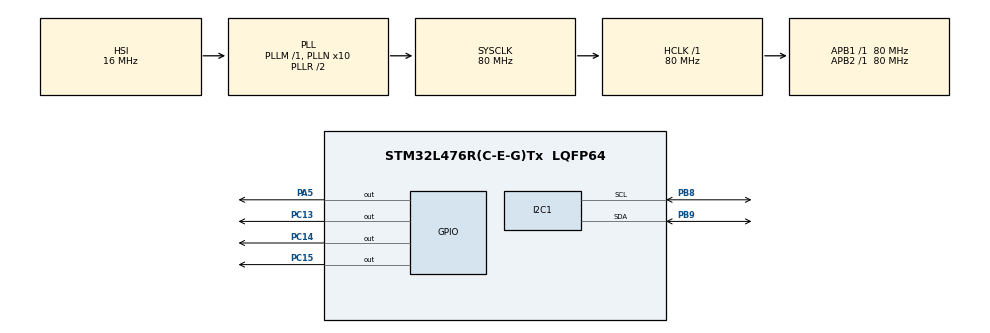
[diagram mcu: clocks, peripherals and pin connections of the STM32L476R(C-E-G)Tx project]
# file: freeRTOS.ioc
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FREERTOS.INCLUDE_eTaskGetState=1
FREERTOS.INCLUDE_pcTaskGetTaskName=1
FREERTOS.INCLUDE_uxTaskGetStackHighWaterMark=1
FREERTOS.INCLUDE_uxTaskGetStackHighWaterMark2=1
FREERTOS.INCLUDE_vTaskCleanUpResources=1
FREERTOS.INCLUDE_xQueueGetMutexHolder=1
FREERTOS.INCLUDE_xSemaphoreGetMutexHolder=1
FREERTOS.INCLUDE_xTaskAbortDelay=1
FREERTOS.INCLUDE_xTaskGetCurrentTaskHandle=1
FREERTOS.INCLUDE_xTaskGetHandle=1
FREERTOS.Tasks01=defaultTask,0,128,StartDefaultTask,Default,NULL,Dynamic,NULL,NULL
FREERTOS.configUSE_NEWLIB_REENTRANT=1
I2C1.Timing=0x10909CEC
Mcu.Family=STM32L4
Mcu.Name=STM32L476R(C-E-G)Tx
Mcu.Package=LQFP64
NVIC.PriorityGroup=NVIC_PRIORITYGROUP_4
PA4.Signal=SPI1_NSS
PA5.Signal=GPIO_Output
PA6.Signal=SPI1_MISO
PA7.Signal=SPI1_MOSI
PB8.Mode=I2C
PB8.Signal=I2C1_SCL
PB9.Mode=I2C
PB9.Signal=I2C1_SDA
PC13.Signal=GPIO_Output
PC14-OSC32_IN\ (PC14).Signal=GPIO_Output
PC15-OSC32_OUT\ (PC15).Signal=GPIO_Output
ProjectManager.HeapSize=0x200
ProjectManager.StackSize=0x400
ProjectManager.TargetToolchain=STM32CubeIDE
RCC.ADCFreq_Value=64000000
RCC.AHBFreq_Value=80000000
RCC.APB1Freq_Value=80000000
RCC.APB1TimFreq_Value=80000000
RCC.APB2Freq_Value=80000000
RCC.APB2TimFreq_Value=80000000
RCC.CortexFreq_Value=80000000
RCC.HCLKFreq_Value=80000000
RCC.HSE_VALUE=8000000
RCC.HSI_VALUE=16000000
RCC.LSE_VALUE=32768
RCC.MSI_VALUE=4000000
RCC.PLLN=10
RCC.PLLSourceVirtual=RCC_PLLSOURCE_HSI
RCC.PREFETCH_ENABLE=1
RCC.SYSCLKFreq_VALUE=80000000
RCC.SYSCLKSource=RCC_SYSCLKSOURCE_PLLCLK
RCC.USBFreq_Value=64000000
RCC.VCOOutputFreq_Value=160000000
VP_FREERTOS_VS_CMSIS_V1.Mode=CMSIS_V1
board=NUCLEO-L476RG

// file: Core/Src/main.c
/* USER CODE BEGIN Header */
/**
  ******************************************************************************
  * @file           : main.c
  * @brief          : Main program body
  ******************************************************************************
  * @attention
  *
  * Copyright (c) 2023 STMicroelectronics.
  * All rights reserved.
  *
  * This software is licensed under terms that can be found in the LICENSE file
  * in the root directory of this software component.
  * If no LICENSE file comes with this software, it is provided AS-IS.
  *
  ******************************************************************************
  */
/* USER CODE END Header */
#include "main.h"
#include "cmsis_os.h"

/* USER CODE BEGIN Includes */
#include "FreeRTOS.h"
#include "task.h"
#include "main.h"
/* USER CODE END Includes */

I2C_HandleTypeDef hi2c1;

osThreadId defaultTaskHandle;

void SystemClock_Config(void);
static void MX_GPIO_Init(void);
static void MX_I2C1_Init(void);
static void MX_SPI1_Init(void);
void StartDefaultTask(void const * argument);

/* USER CODE BEGIN 0 */

/* USER CODE BEGIN PFP */
static void led_green_function(void* params);
static void led_orange_function(void* params);
static void led_red_function(void* params);
//static void led_blue_function(void* params);
/* USER CODE END 0 */

int main(void)
{

  /* MCU Configuration--------------------------------------------------------*/

  /* Reset of all peripherals, Initializes the Flash interface and the Systick. */
  HAL_Init();

  /* Configure the system clock */
  SystemClock_Config();

  /* Initialize all configured peripherals */
  MX_GPIO_Init();
  MX_I2C1_Init();

  /* Create the thread(s) */
  /* definition and creation of defaultTask */
  osThreadDef(defaultTask, StartDefaultTask, osPriorityNormal, 0, 128);
  defaultTaskHandle = osThreadCreate(osThread(defaultTask), NULL);

  TaskHandle_t led_green, led_red, led_orange; //led_blue, button;
	BaseType_t status;
  status = xTaskCreate(led_green_function, "Green LED", 200, NULL, 2, &led_green);
  configASSERT(status == pdPASS);

	status = xTaskCreate(led_orange_function, "Orange LED", 200, NULL, 2, &led_orange);
	  configASSERT(status == pdPASS);

	  //Task 3
	  status = xTaskCreate(led_red_function, "Red LED", 200, NULL, 2, &led_red);
	  configASSERT(status == pdPASS);

	  //Task 4
	 // status = xTaskCreate(led_blue_function, "Blue LED", 200, NULL, 2, &led_blue);

	  vTaskStartScheduler();
  /* Start scheduler */
  osKernelStart();
  /* We should never get here as control is now taken by the scheduler */
  /* Infinite loop */
  while (1)
  {

  }
}

void SystemClock_Config(void)
{
  RCC_OscInitTypeDef RCC_OscInitStruct = {0};
  RCC_ClkInitTypeDef RCC_ClkInitStruct = {0};

  /** Configure the main internal regulator output voltage
  */
  if (HAL_PWREx_ControlVoltageScaling(PWR_REGULATOR_VOLTAGE_SCALE1) != HAL_OK)
  {
    Error_Handler();
  }

  /** Initializes the RCC Oscillators according to the specified parameters
  * in the RCC_OscInitTypeDef structure.
  */
  RCC_OscInitStruct.OscillatorType = RCC_OSCILLATORTYPE_HSI;
  RCC_OscInitStruct.HSIState = RCC_HSI_ON;
  RCC_OscInitStruct.HSICalibrationValue = RCC_HSICALIBRATION_DEFAULT;
  RCC_OscInitStruct.PLL.PLLState = RCC_PLL_ON;
  RCC_OscInitStruct.PLL.PLLSource = RCC_PLLSOURCE_HSI;
  RCC_OscInitStruct.PLL.PLLM = 1;
  RCC_OscInitStruct.PLL.PLLN = 10;
  RCC_OscInitStruct.PLL.PLLP = RCC_PLLP_DIV7;
  RCC_OscInitStruct.PLL.PLLQ = RCC_PLLQ_DIV2;
  RCC_OscInitStruct.PLL.PLLR = RCC_PLLR_DIV2;
  if (HAL_RCC_OscConfig(&RCC_OscInitStruct) != HAL_OK)
  {
    Error_Handler();
  }

  /** Initializes the CPU, AHB and APB buses clocks
  */
  RCC_ClkInitStruct.ClockType = RCC_CLOCKTYPE_HCLK|RCC_CLOCKTYPE_SYSCLK
                              |RCC_CLOCKTYPE_PCLK1|RCC_CLOCKTYPE_PCLK2;
  RCC_ClkInitStruct.SYSCLKSource = RCC_SYSCLKSOURCE_PLLCLK;
  RCC_ClkInitStruct.AHBCLKDivider = RCC_SYSCLK_DIV1;
  RCC_ClkInitStruct.APB1CLKDivider = RCC_HCLK_DIV1;
  RCC_ClkInitStruct.APB2CLKDivider = RCC_HCLK_DIV1;

  if (HAL_RCC_ClockConfig(&RCC_ClkInitStruct, FLASH_LATENCY_4) != HAL_OK)
  {
    Error_Handler();
  }
}

static void MX_I2C1_Init(void)
{

  hi2c1.Instance = I2C1;
  hi2c1.Init.Timing = 0x10909CEC;
  hi2c1.Init.OwnAddress1 = 0;
  hi2c1.Init.AddressingMode = I2C_ADDRESSINGMODE_7BIT;
  hi2c1.Init.DualAddressMode = I2C_DUALADDRESS_DISABLE;
  hi2c1.Init.OwnAddress2 = 0;
  hi2c1.Init.OwnAddress2Masks = I2C_OA2_NOMASK;
  hi2c1.Init.GeneralCallMode = I2C_GENERALCALL_DISABLE;
  hi2c1.Init.NoStretchMode = I2C_NOSTRETCH_DISABLE;
  if (HAL_I2C_Init(&hi2c1) != HAL_OK)
  {
    Error_Handler();
  }

  /** Configure Analogue filter
  */
  if (HAL_I2CEx_ConfigAnalogFilter(&hi2c1, I2C_ANALOGFILTER_ENABLE) != HAL_OK)
  {
    Error_Handler();
  }

  /** Configure Digital filter
  */
  if (HAL_I2CEx_ConfigDigitalFilter(&hi2c1, 0) != HAL_OK)
  {
    Error_Handler();
  }

}

static void MX_GPIO_Init(void)
{
  GPIO_InitTypeDef GPIO_InitStruct = {0};

  /* GPIO Ports Clock Enable */
  __HAL_RCC_GPIOC_CLK_ENABLE();
  __HAL_RCC_GPIOA_CLK_ENABLE();
  __HAL_RCC_GPIOB_CLK_ENABLE();

  /*Configure GPIO pin Output Level */
  HAL_GPIO_WritePin(GPIOC, GPIO_PIN_13|GPIO_PIN_14|GPIO_PIN_15, GPIO_PIN_RESET);

  /*Configure GPIO pins : PC13 PC14 PC15 */
  GPIO_InitStruct.Pin = GPIO_PIN_13|GPIO_PIN_14|GPIO_PIN_15;
  GPIO_InitStruct.Mode = GPIO_MODE_OUTPUT_PP;
  GPIO_InitStruct.Pull = GPIO_NOPULL;
  GPIO_InitStruct.Speed = GPIO_SPEED_FREQ_LOW;
  HAL_GPIO_Init(GPIOC, &GPIO_InitStruct);

}

void StartDefaultTask(void const * argument)
{
  for(;;)
  {
    osDelay(1);
  }
}
static void led_green_function(void* params)
{
	TickType_t last_wakeup = xTaskGetTickCount();
	while(1)
	{
		printf("Green LED Task\n");
		HAL_GPIO_TogglePin(GPIOC, 13);
//		HAL_Delay(1000);
		vTaskDelay( pdMS_TO_TICKS( 1000 ) );
//		vTaskDelayUntil(&last_wakeup, pdMS_TO_TICKS( 250 ) );
	}
}

static void led_orange_function(void* params)
{
	TickType_t last_wakeup = xTaskGetTickCount();
	while(1)
	{
		printf("Orange LED Task\n");
		HAL_GPIO_TogglePin(GPIOC, 14);
//		HAL_Delay(750);
		vTaskDelay( pdMS_TO_TICKS( 750 ) );
//		vTaskDelayUntil(&last_wakeup, pdMS_TO_TICKS( 500 ) );
	}
}

static void led_red_function(void* params)
{
	TickType_t last_wakeup = xTaskGetTickCount();
	while(1)
	{
		printf("Red LED Task\n");
		HAL_GPIO_TogglePin(GPIOA, 5);

//		HAL_Delay(500);
		vTaskDelay( pdMS_TO_TICKS( 500 ) );
//		vTaskDelayUntil(&last_wakeup, pdMS_TO_TICKS( 750 ) );
	}
}

/*static void led_blue_function(void* params)
{
	TickType_t last_wakeup = xTaskGetTickCount();
	while(1)
	{
		printf("Blue LED Task\n");
		HAL_GPIO_TogglePin(GPIOD, LD6_Pin);
//		HAL_Delay(500);
		vTaskDelay( pdMS_TO_TICKS( 250 ) );
//		vTaskDelayUntil(&last_wakeup, pdMS_TO_TICKS( 1000 ) );
	}
}*/

/* USER CODE END 4 */

void Error_Handler(void)
{
  __disable_irq();
  while (1)
  {
  }
}
